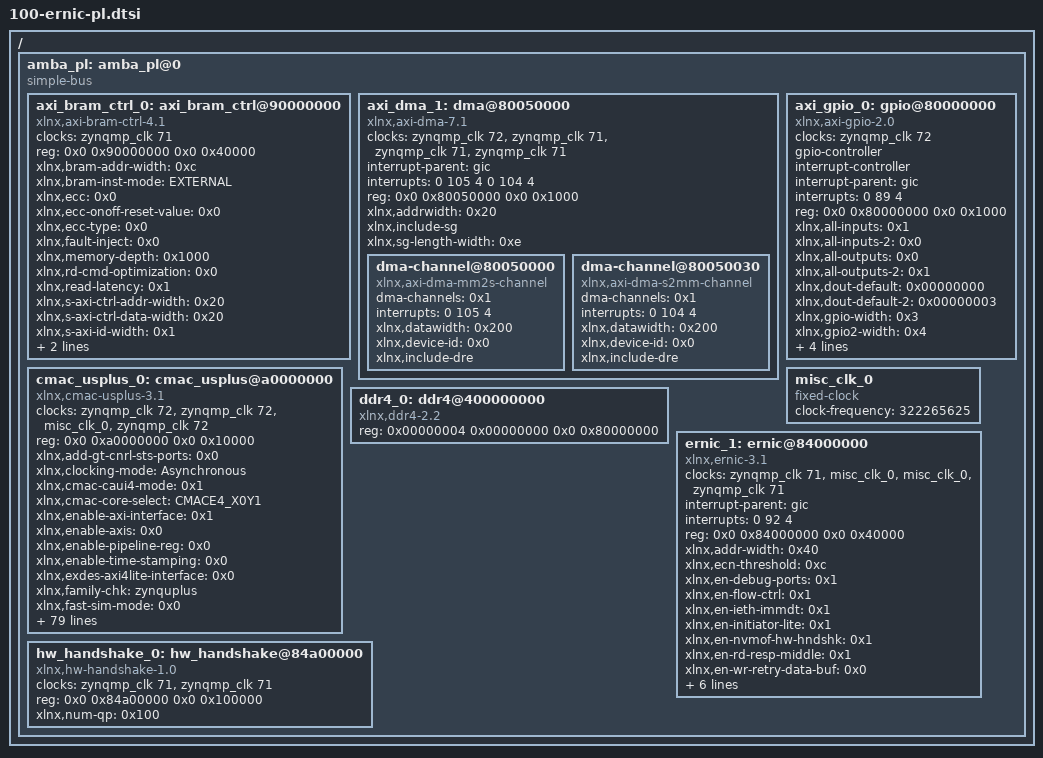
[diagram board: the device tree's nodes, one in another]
/*
 * CAUTION: This file is automatically generated by Xilinx.
 * Version:  
 * Today is: Wed Mar  8 00:44:19 2023
 */


/ {
	amba_pl: amba_pl@0 {
		#address-cells = <2>;
		#size-cells = <2>;
		compatible = "simple-bus";
		ranges ;
		axi_bram_ctrl_0: axi_bram_ctrl@90000000 {
			clock-names = "s_axi_aclk";
			clocks = <&zynqmp_clk 71>;
			compatible = "xlnx,axi-bram-ctrl-4.1";
			reg = <0x0 0x90000000 0x0 0x40000>;
			xlnx,bram-addr-width = <0xc>;
			xlnx,bram-inst-mode = "EXTERNAL";
			xlnx,ecc = <0x0>;
			xlnx,ecc-onoff-reset-value = <0x0>;
			xlnx,ecc-type = <0x0>;
			xlnx,fault-inject = <0x0>;
			xlnx,memory-depth = <0x1000>;
			xlnx,rd-cmd-optimization = <0x0>;
			xlnx,read-latency = <0x1>;
			xlnx,s-axi-ctrl-addr-width = <0x20>;
			xlnx,s-axi-ctrl-data-width = <0x20>;
			xlnx,s-axi-id-width = <0x1>;
			xlnx,s-axi-supports-narrow-burst = <0x0>;
			xlnx,single-port-bram = <0x1>;
		};
		axi_dma_1: dma@80050000 {
			#dma-cells = <1>;
			clock-names = "s_axi_lite_aclk", "m_axi_sg_aclk", "m_axi_mm2s_aclk", "m_axi_s2mm_aclk";
			clocks = <&zynqmp_clk 72>, <&zynqmp_clk 71>, <&zynqmp_clk 71>, <&zynqmp_clk 71>;
			compatible = "xlnx,axi-dma-7.1", "xlnx,axi-dma-1.00.a";
			interrupt-names = "mm2s_introut", "s2mm_introut";
			interrupt-parent = <&gic>;
			interrupts = <0 105 4 0 104 4>;
			reg = <0x0 0x80050000 0x0 0x1000>;
			xlnx,addrwidth = <0x20>;
			xlnx,include-sg ;
			xlnx,sg-length-width = <0xe>;
			dma-channel@80050000 {
				compatible = "xlnx,axi-dma-mm2s-channel";
				dma-channels = <0x1>;
				interrupts = <0 105 4>;
				xlnx,datawidth = <0x200>;
				xlnx,device-id = <0x0>;
				xlnx,include-dre ;
			};
			dma-channel@80050030 {
				compatible = "xlnx,axi-dma-s2mm-channel";
				dma-channels = <0x1>;
				interrupts = <0 104 4>;
				xlnx,datawidth = <0x200>;
				xlnx,device-id = <0x0>;
				xlnx,include-dre ;
			};
		};
		axi_gpio_0: gpio@80000000 {
			#gpio-cells = <3>;
			#interrupt-cells = <2>;
			clock-names = "s_axi_aclk";
			clocks = <&zynqmp_clk 72>;
			compatible = "xlnx,axi-gpio-2.0", "xlnx,xps-gpio-1.00.a";
			gpio-controller ;
			interrupt-controller ;
			interrupt-names = "ip2intc_irpt";
			interrupt-parent = <&gic>;
			interrupts = <0 89 4>;
			reg = <0x0 0x80000000 0x0 0x1000>;
			xlnx,all-inputs = <0x1>;
			xlnx,all-inputs-2 = <0x0>;
			xlnx,all-outputs = <0x0>;
			xlnx,all-outputs-2 = <0x1>;
			xlnx,dout-default = <0x00000000>;
			xlnx,dout-default-2 = <0x00000003>;
			xlnx,gpio-width = <0x3>;
			xlnx,gpio2-width = <0x4>;
			xlnx,interrupt-present = <0x1>;
			xlnx,is-dual = <0x1>;
			xlnx,tri-default = <0xFFFFFFFF>;
			xlnx,tri-default-2 = <0xFFFFFFFF>;
		};
		cmac_usplus_0: cmac_usplus@a0000000 {
			clock-names = "s_axi_aclk", "init_clk", "rx_clk", "drp_clk";
			clocks = <&zynqmp_clk 72>, <&zynqmp_clk 72>, <&misc_clk_0>, <&zynqmp_clk 72>;
			compatible = "xlnx,cmac-usplus-3.1";
			reg = <0x0 0xa0000000 0x0 0x10000>;
			xlnx,add-gt-cnrl-sts-ports = <0x0>;
			xlnx,clocking-mode = "Asynchronous";
			xlnx,cmac-caui4-mode = <0x1>;
			xlnx,cmac-core-select = "CMACE4_X0Y1";
			xlnx,enable-axi-interface = <0x1>;
			xlnx,enable-axis = <0x0>;
			xlnx,enable-pipeline-reg = <0x0>;
			xlnx,enable-time-stamping = <0x0>;
			xlnx,exdes-axi4lite-interface = <0x0>;
			xlnx,family-chk = "zynquplus";
			xlnx,fast-sim-mode = <0x0>;
			xlnx,gt-drp-clk = "100.00";
			xlnx,gt-group-select = <0x0>;
			xlnx,gt-location = <0x1>;
			xlnx,gt-ref-clk-freq = "322.265625";
			xlnx,gt-rx-buffer-bypass = <0x0>;
			xlnx,gt-type = "GTY";
			xlnx,include-an-lt-tx-trainer = <0x0>;
			xlnx,include-auto-neg-lt-logic = <0x0>;
			xlnx,include-rs-fec = <0x1>;
			xlnx,include-shared-logic = <0x2>;
			xlnx,include-statistics-counters = <0x1>;
			xlnx,ins-loss-nyq = <0xc>;
			xlnx,lane1-gt-loc = "X0Y12";
			xlnx,lane10-gt-loc = "NA";
			xlnx,lane2-gt-loc = "X0Y13";
			xlnx,lane3-gt-loc = "X0Y14";
			xlnx,lane4-gt-loc = "X0Y15";
			xlnx,lane5-gt-loc = "NA";
			xlnx,lane6-gt-loc = "NA";
			xlnx,lane7-gt-loc = "NA";
			xlnx,lane8-gt-loc = "NA";
			xlnx,lane9-gt-loc = "NA";
			xlnx,line-rate = "25.78125";
			xlnx,num-lanes = <0x4>;
			xlnx,operating-mode = <0x3>;
			xlnx,pll-type = "QPLL0";
			xlnx,ptp-transpclk-mode = <0x0>;
			xlnx,qpll-fracn-numerator = <0x0>;
			xlnx,rs-fec-core-sel = "CMACE4_X0Y0";
			xlnx,rs-fec-transcode-bypass = <0x0>;
			xlnx,rx-check-ack = <0x0>;
			xlnx,rx-check-preamble = <0x0>;
			xlnx,rx-check-sfd = <0x0>;
			xlnx,rx-delete-fcs = <0x1>;
			xlnx,rx-eq-mode = "AUTO";
			xlnx,rx-etype-gcp = <0x8808>;
			xlnx,rx-etype-gpp = <0x8808>;
			xlnx,rx-etype-pcp = <0x8808>;
			xlnx,rx-etype-ppp = <0x8808>;
			xlnx,rx-flow-control = <0x1>;
			xlnx,rx-forward-control-frames = <0x0>;
			xlnx,rx-frame-crc-checking = "Enable FCS Stripping";
			xlnx,rx-gt-buffer = <0x1>;
			xlnx,rx-ignore-fcs = <0x0>;
			xlnx,rx-max-packet-len = <0x2580>;
			xlnx,rx-min-packet-len = <0x40>;
			xlnx,rx-opcode-gpp = <0x0001>;
			xlnx,rx-opcode-max-gcp = <0xFFFF>;
			xlnx,rx-opcode-max-pcp = <0xFFFF>;
			xlnx,rx-opcode-min-gcp = <0x0000>;
			xlnx,rx-opcode-min-pcp = <0x0000>;
			xlnx,rx-opcode-ppp = <0x0101>;
			xlnx,rx-pause-da-mcast = <0x00000180 0xC2000001>;
			xlnx,rx-pause-da-ucast = <0x00000000 0x00000000>;
			xlnx,rx-pause-sa = <0x00000000 0x00000000>;
			xlnx,rx-process-lfi = <0x0>;
			xlnx,statistics-regs-type = <0x0>;
			xlnx,tx-da-gpp = <0x00000180 0xC2000001>;
			xlnx,tx-da-ppp = <0x00000180 0xC2000001>;
			xlnx,tx-ethertype-gpp = <0x8808>;
			xlnx,tx-ethertype-ppp = <0x8808>;
			xlnx,tx-fcs-ins-enable = <0x1>;
			xlnx,tx-flow-control = <0x1>;
			xlnx,tx-frame-crc-checking = "Enable FCS Insertion";
			xlnx,tx-ignore-fcs = <0x1>;
			xlnx,tx-ipg-value = <0xc>;
			xlnx,tx-lane0-vlm-bip7-override = <0x0>;
			xlnx,tx-opcode-gpp = <0x0001>;
			xlnx,tx-opcode-ppp = <0x0101>;
			xlnx,tx-otn-interface = <0x0>;
			xlnx,tx-ptp-1step-enable = <0x0>;
			xlnx,tx-ptp-latency-adjust = <0x0>;
			xlnx,tx-ptp-vlane-adjust-mode = <0x0>;
			xlnx,tx-sa-gpp = <0x00000000 0x00000000>;
			xlnx,tx-sa-ppp = <0x00000000 0x00000000>;
			xlnx,update-lt-coeff = <0x0>;
			xlnx,user-interface = "AXIS";
		};
		misc_clk_0: misc_clk_0 {
			#clock-cells = <0>;
			clock-frequency = <322265625>;
			compatible = "fixed-clock";
		};
		ddr4_0: ddr4@400000000 {
			compatible = "xlnx,ddr4-2.2";
			reg = <0x00000004 0x00000000 0x0 0x80000000>;
		};
		ernic_1: ernic@84000000 {
			clock-names = "m_axi_aclk", "cmac_rx_clk", "cmac_tx_clk", "s_axi_lite_aclk";
			clocks = <&zynqmp_clk 71>, <&misc_clk_0>, <&misc_clk_0>, <&zynqmp_clk 71>;
			compatible = "xlnx,ernic-3.1";
			interrupt-names = "rnic_intr";
			interrupt-parent = <&gic>;
			interrupts = <0 92 4>;
			reg = <0x0 0x84000000 0x0 0x40000>;
			xlnx,addr-width = <0x40>;
			xlnx,ecn-threshold = <0xc>;
			xlnx,en-debug-ports = <0x1>;
			xlnx,en-flow-ctrl = <0x1>;
			xlnx,en-ieth-immdt = <0x1>;
			xlnx,en-initiator-lite = <0x1>;
			xlnx,en-nvmof-hw-hndshk = <0x1>;
			xlnx,en-rd-resp-middle = <0x1>;
			xlnx,en-wr-retry-data-buf = <0x0>;
			xlnx,max-rd-os = <0x10>;
			xlnx,max-sgl-depth = <0x100>;
			xlnx,max-wr-retry-data-buf-depth = <0x200>;
			xlnx,num-pd = <0x100>;
			xlnx,num-qp = <0x100>;
			xlnx,osq-psn-width = <0x10>;
		};
		hw_handshake_0: hw_handshake@84a00000 {
			clock-names = "s_axi_lite_aclk", "m_axi_clk";
			clocks = <&zynqmp_clk 71>, <&zynqmp_clk 71>;
			compatible = "xlnx,hw-handshake-1.0";
			reg = <0x0 0x84a00000 0x0 0x100000>;
			xlnx,num-qp = <0x100>;
		};
	};
};
